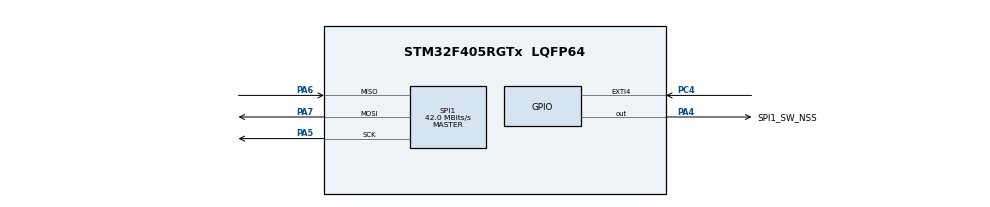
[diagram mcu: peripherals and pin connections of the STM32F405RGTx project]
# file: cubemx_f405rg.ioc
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Dma.Request0=SPI1_RX
Dma.Request1=SPI1_TX
Dma.SPI1_RX.0.Direction=DMA_PERIPH_TO_MEMORY
Dma.SPI1_RX.0.FIFOMode=DMA_FIFOMODE_DISABLE
Dma.SPI1_RX.0.Instance=DMA2_Stream0
Dma.SPI1_RX.0.MemDataAlignment=DMA_MDATAALIGN_BYTE
Dma.SPI1_RX.0.MemInc=DMA_MINC_ENABLE
Dma.SPI1_RX.0.Mode=DMA_NORMAL
Dma.SPI1_RX.0.PeriphDataAlignment=DMA_PDATAALIGN_BYTE
Dma.SPI1_RX.0.PeriphInc=DMA_PINC_DISABLE
Dma.SPI1_RX.0.Priority=DMA_PRIORITY_LOW
Dma.SPI1_TX.1.Direction=DMA_MEMORY_TO_PERIPH
Dma.SPI1_TX.1.FIFOMode=DMA_FIFOMODE_DISABLE
Dma.SPI1_TX.1.Instance=DMA2_Stream3
Dma.SPI1_TX.1.MemDataAlignment=DMA_MDATAALIGN_BYTE
Dma.SPI1_TX.1.MemInc=DMA_MINC_ENABLE
Dma.SPI1_TX.1.Mode=DMA_NORMAL
Dma.SPI1_TX.1.PeriphDataAlignment=DMA_PDATAALIGN_BYTE
Dma.SPI1_TX.1.PeriphInc=DMA_PINC_DISABLE
Dma.SPI1_TX.1.Priority=DMA_PRIORITY_LOW
Mcu.Family=STM32F4
Mcu.Name=STM32F405RGTx
Mcu.Package=LQFP64
NVIC.DMA2_Stream0_IRQn=true\:0\:0\:false\:false\:true\:false\:true
NVIC.DMA2_Stream3_IRQn=true\:0\:0\:false\:false\:true\:false\:true
NVIC.EXTI4_IRQn=true\:0\:0\:false\:false\:true\:true\:true
NVIC.PriorityGroup=NVIC_PRIORITYGROUP_4
NVIC.SPI1_IRQn=true\:0\:0\:false\:false\:true\:true\:true
PA13.Mode=Serial_Wire
PA13.Signal=SYS_JTMS-SWDIO
PA14.Mode=Serial_Wire
PA14.Signal=SYS_JTCK-SWCLK
PA4.GPIO_Label=SPI1_SW_NSS
PA4.Signal=GPIO_Output
PA5.Mode=Full_Duplex_Master
PA5.Signal=SPI1_SCK
PA6.Mode=Full_Duplex_Master
PA6.Signal=SPI1_MISO
PA7.Mode=Full_Duplex_Master
PA7.Signal=SPI1_MOSI
PC4.Signal=GPXTI4
PH0-OSC_IN.Mode=HSE-External-Oscillator
PH0-OSC_IN.Signal=RCC_OSC_IN
PH1-OSC_OUT.Mode=HSE-External-Oscillator
PH1-OSC_OUT.Signal=RCC_OSC_OUT
ProjectManager.HeapSize=0x200
ProjectManager.StackSize=0x400
ProjectManager.TargetToolchain=Makefile
RCC.48MHZClocksFreq_Value=84000000
RCC.AHBFreq_Value=168000000
RCC.APB1CLKDivider=RCC_HCLK_DIV4
RCC.APB1Freq_Value=42000000
RCC.APB1TimFreq_Value=84000000
RCC.APB2CLKDivider=RCC_HCLK_DIV2
RCC.APB2Freq_Value=84000000
RCC.APB2TimFreq_Value=168000000
RCC.CortexFreq_Value=168000000
RCC.HCLKFreq_Value=168000000
RCC.HSE_VALUE=8000000
RCC.HSI_VALUE=16000000
RCC.LSE_VALUE=32768
RCC.PLLM=4
RCC.PLLN=168
RCC.PLLSourceVirtual=RCC_PLLSOURCE_HSE
RCC.RCC_RTC_Clock_SourceVirtual=RCC_RTCCLKSOURCE_HSE_DIV8
RCC.RCC_RTC_Clock_Source_FROM_HSE=RCC_RTCCLKSOURCE_HSE_DIV8
RCC.SYSCLKFreq_VALUE=168000000
RCC.SYSCLKSource=RCC_SYSCLKSOURCE_PLLCLK
RCC.VCOOutputFreq_Value=336000000
SPI1.CalculateBaudRate=42.0 MBits/s
SPI1.Direction=SPI_DIRECTION_2LINES
SPI1.Mode=SPI_MODE_MASTER
SPI1.VirtualType=VM_MASTER
VP_RTC_VS_RTC_Activate.Mode=RTC_Enabled
board=custom

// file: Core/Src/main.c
/* USER CODE BEGIN Header */
/**
  ******************************************************************************
  * @file           : main.c
  * @brief          : Main program body
  ******************************************************************************
  * @attention
  *
  * <h2><center>&copy; Copyright (c) 2022 STMicroelectronics.
  * All rights reserved.</center></h2>
  *
  * This software component is licensed by ST under BSD 3-Clause license,
  * the "License"; You may not use this file except in compliance with the
  * License. You may obtain a copy of the License at:
  *                        opensource.org/licenses/BSD-3-Clause
  *
  ******************************************************************************
  */
/* USER CODE END Header */
#include "main.h"

void SystemClock_Config(void);
static void MX_GPIO_Init(void);
static void MX_DMA_Init(void);
static void MX_SPI1_Init(void);
static void MX_RTC_Init(void);

int main(void)
{

  /* MCU Configuration--------------------------------------------------------*/

  /* Reset of all peripherals, Initializes the Flash interface and the Systick. */

  LL_APB2_GRP1_EnableClock(LL_APB2_GRP1_PERIPH_SYSCFG);
  LL_APB1_GRP1_EnableClock(LL_APB1_GRP1_PERIPH_PWR);

  NVIC_SetPriorityGrouping(NVIC_PRIORITYGROUP_4);

  /* System interrupt init*/
  /* SysTick_IRQn interrupt configuration */
  NVIC_SetPriority(SysTick_IRQn, NVIC_EncodePriority(NVIC_GetPriorityGrouping(),15, 0));

  /* Configure the system clock */
  SystemClock_Config();

  /* Initialize all configured peripherals */
  MX_GPIO_Init();
  MX_DMA_Init();
  MX_SPI1_Init();
  MX_RTC_Init();

  /* Infinite loop */
  while (1)
  {

  }
}

void SystemClock_Config(void)
{
  LL_FLASH_SetLatency(LL_FLASH_LATENCY_5);
  while(LL_FLASH_GetLatency()!= LL_FLASH_LATENCY_5)
  {
  }
  LL_PWR_SetRegulVoltageScaling(LL_PWR_REGU_VOLTAGE_SCALE1);
  LL_RCC_HSE_Enable();

   /* Wait till HSE is ready */
  while(LL_RCC_HSE_IsReady() != 1)
  {

  }
  LL_PWR_EnableBkUpAccess();
  LL_RCC_PLL_ConfigDomain_SYS(LL_RCC_PLLSOURCE_HSE, LL_RCC_PLLM_DIV_4, 168, LL_RCC_PLLP_DIV_2);
  LL_RCC_PLL_Enable();

   /* Wait till PLL is ready */
  while(LL_RCC_PLL_IsReady() != 1)
  {

  }
  LL_RCC_SetAHBPrescaler(LL_RCC_SYSCLK_DIV_1);
  LL_RCC_SetAPB1Prescaler(LL_RCC_APB1_DIV_4);
  LL_RCC_SetAPB2Prescaler(LL_RCC_APB2_DIV_2);
  LL_RCC_SetSysClkSource(LL_RCC_SYS_CLKSOURCE_PLL);

   /* Wait till System clock is ready */
  while(LL_RCC_GetSysClkSource() != LL_RCC_SYS_CLKSOURCE_STATUS_PLL)
  {

  }
  LL_Init1msTick(168000000);
  LL_SetSystemCoreClock(168000000);
}

static void MX_RTC_Init(void)
{

  LL_RTC_InitTypeDef RTC_InitStruct = {0};

  if(LL_RCC_GetRTCClockSource() != LL_RCC_RTC_CLKSOURCE_HSE)
  {
    LL_RCC_ForceBackupDomainReset();
    LL_RCC_ReleaseBackupDomainReset();
  LL_RCC_SetRTCClockSource(LL_RCC_RTC_CLKSOURCE_HSE);
  }
  LL_RCC_SetRTC_HSEPrescaler(LL_RCC_RTC_HSE_DIV_8);

  /* Peripheral clock enable */
  LL_RCC_EnableRTC();

  /** Initialize RTC and set the Time and Date
  */
  RTC_InitStruct.HourFormat = LL_RTC_HOURFORMAT_24HOUR;
  RTC_InitStruct.AsynchPrescaler = 127;
  RTC_InitStruct.SynchPrescaler = 255;
  LL_RTC_Init(RTC, &RTC_InitStruct);
  LL_RTC_SetAsynchPrescaler(RTC, 127);
  LL_RTC_SetSynchPrescaler(RTC, 255);

}

static void MX_SPI1_Init(void)
{

  LL_SPI_InitTypeDef SPI_InitStruct = {0};

  LL_GPIO_InitTypeDef GPIO_InitStruct = {0};

  /* Peripheral clock enable */
  LL_APB2_GRP1_EnableClock(LL_APB2_GRP1_PERIPH_SPI1);

  LL_AHB1_GRP1_EnableClock(LL_AHB1_GRP1_PERIPH_GPIOA);
  /**SPI1 GPIO Configuration
  PA5   ------> SPI1_SCK
  PA6   ------> SPI1_MISO
  PA7   ------> SPI1_MOSI
  */
  GPIO_InitStruct.Pin = LL_GPIO_PIN_5|LL_GPIO_PIN_6|LL_GPIO_PIN_7;
  GPIO_InitStruct.Mode = LL_GPIO_MODE_ALTERNATE;
  GPIO_InitStruct.Speed = LL_GPIO_SPEED_FREQ_VERY_HIGH;
  GPIO_InitStruct.OutputType = LL_GPIO_OUTPUT_PUSHPULL;
  GPIO_InitStruct.Pull = LL_GPIO_PULL_NO;
  GPIO_InitStruct.Alternate = LL_GPIO_AF_5;
  LL_GPIO_Init(GPIOA, &GPIO_InitStruct);

  /* SPI1 DMA Init */

  /* SPI1_RX Init */
  LL_DMA_SetChannelSelection(DMA2, LL_DMA_STREAM_0, LL_DMA_CHANNEL_3);

  LL_DMA_SetDataTransferDirection(DMA2, LL_DMA_STREAM_0, LL_DMA_DIRECTION_PERIPH_TO_MEMORY);

  LL_DMA_SetStreamPriorityLevel(DMA2, LL_DMA_STREAM_0, LL_DMA_PRIORITY_LOW);

  LL_DMA_SetMode(DMA2, LL_DMA_STREAM_0, LL_DMA_MODE_NORMAL);

  LL_DMA_SetPeriphIncMode(DMA2, LL_DMA_STREAM_0, LL_DMA_PERIPH_NOINCREMENT);

  LL_DMA_SetMemoryIncMode(DMA2, LL_DMA_STREAM_0, LL_DMA_MEMORY_INCREMENT);

  LL_DMA_SetPeriphSize(DMA2, LL_DMA_STREAM_0, LL_DMA_PDATAALIGN_BYTE);

  LL_DMA_SetMemorySize(DMA2, LL_DMA_STREAM_0, LL_DMA_MDATAALIGN_BYTE);

  LL_DMA_DisableFifoMode(DMA2, LL_DMA_STREAM_0);

  /* SPI1_TX Init */
  LL_DMA_SetChannelSelection(DMA2, LL_DMA_STREAM_3, LL_DMA_CHANNEL_3);

  LL_DMA_SetDataTransferDirection(DMA2, LL_DMA_STREAM_3, LL_DMA_DIRECTION_MEMORY_TO_PERIPH);

  LL_DMA_SetStreamPriorityLevel(DMA2, LL_DMA_STREAM_3, LL_DMA_PRIORITY_LOW);

  LL_DMA_SetMode(DMA2, LL_DMA_STREAM_3, LL_DMA_MODE_NORMAL);

  LL_DMA_SetPeriphIncMode(DMA2, LL_DMA_STREAM_3, LL_DMA_PERIPH_NOINCREMENT);

  LL_DMA_SetMemoryIncMode(DMA2, LL_DMA_STREAM_3, LL_DMA_MEMORY_INCREMENT);

  LL_DMA_SetPeriphSize(DMA2, LL_DMA_STREAM_3, LL_DMA_PDATAALIGN_BYTE);

  LL_DMA_SetMemorySize(DMA2, LL_DMA_STREAM_3, LL_DMA_MDATAALIGN_BYTE);

  LL_DMA_DisableFifoMode(DMA2, LL_DMA_STREAM_3);

  /* SPI1 interrupt Init */
  NVIC_SetPriority(SPI1_IRQn, NVIC_EncodePriority(NVIC_GetPriorityGrouping(),0, 0));
  NVIC_EnableIRQ(SPI1_IRQn);

  /* USER CODE BEGIN SPI1_Init 1 */
  /* (5) Enable DMA interrupts complete/error */
  LL_DMA_EnableIT_TC(DMA2, LL_DMA_STREAM_0);
  LL_DMA_EnableIT_TE(DMA2, LL_DMA_STREAM_0);

  LL_DMA_EnableIT_TC(DMA2, LL_DMA_STREAM_3);
  LL_DMA_EnableIT_TE(DMA2, LL_DMA_STREAM_3);

  /* USER CODE END SPI1_Init 1 */
  /* SPI1 parameter configuration*/
  SPI_InitStruct.TransferDirection = LL_SPI_FULL_DUPLEX;
  SPI_InitStruct.Mode = LL_SPI_MODE_MASTER;
  SPI_InitStruct.DataWidth = LL_SPI_DATAWIDTH_8BIT;
  SPI_InitStruct.ClockPolarity = LL_SPI_POLARITY_LOW;
  SPI_InitStruct.ClockPhase = LL_SPI_PHASE_1EDGE;
  SPI_InitStruct.NSS = LL_SPI_NSS_SOFT;
  SPI_InitStruct.BaudRate = LL_SPI_BAUDRATEPRESCALER_DIV2;
  SPI_InitStruct.BitOrder = LL_SPI_MSB_FIRST;
  SPI_InitStruct.CRCCalculation = LL_SPI_CRCCALCULATION_DISABLE;
  SPI_InitStruct.CRCPoly = 10;
  LL_SPI_Init(SPI1, &SPI_InitStruct);
  LL_SPI_SetStandard(SPI1, LL_SPI_PROTOCOL_MOTOROLA);
  /* USER CODE BEGIN SPI1_Init 2 */

  /* Configure SPI1 DMA transfer interrupts */
  /* Enable DMA RX Interrupt */
  LL_SPI_EnableDMAReq_RX(SPI1);
  /* Enable DMA TX Interrupt */
  LL_SPI_EnableDMAReq_TX(SPI1);

  /* USER CODE END SPI1_Init 2 */

}

static void MX_DMA_Init(void)
{

  /* Init with LL driver */
  /* DMA controller clock enable */
  LL_AHB1_GRP1_EnableClock(LL_AHB1_GRP1_PERIPH_DMA2);

  /* DMA interrupt init */
  /* DMA2_Stream0_IRQn interrupt configuration */
  NVIC_SetPriority(DMA2_Stream0_IRQn, NVIC_EncodePriority(NVIC_GetPriorityGrouping(),0, 0));
  NVIC_EnableIRQ(DMA2_Stream0_IRQn);
  /* DMA2_Stream3_IRQn interrupt configuration */
  NVIC_SetPriority(DMA2_Stream3_IRQn, NVIC_EncodePriority(NVIC_GetPriorityGrouping(),0, 0));
  NVIC_EnableIRQ(DMA2_Stream3_IRQn);

}

static void MX_GPIO_Init(void)
{
  LL_EXTI_InitTypeDef EXTI_InitStruct = {0};
  LL_GPIO_InitTypeDef GPIO_InitStruct = {0};

  /* GPIO Ports Clock Enable */
  LL_AHB1_GRP1_EnableClock(LL_AHB1_GRP1_PERIPH_GPIOH);
  LL_AHB1_GRP1_EnableClock(LL_AHB1_GRP1_PERIPH_GPIOA);
  LL_AHB1_GRP1_EnableClock(LL_AHB1_GRP1_PERIPH_GPIOC);

  /**/
  LL_GPIO_ResetOutputPin(SPI1_SW_NSS_GPIO_Port, SPI1_SW_NSS_Pin);

  /**/
  GPIO_InitStruct.Pin = SPI1_SW_NSS_Pin;
  GPIO_InitStruct.Mode = LL_GPIO_MODE_OUTPUT;
  GPIO_InitStruct.Speed = LL_GPIO_SPEED_FREQ_LOW;
  GPIO_InitStruct.OutputType = LL_GPIO_OUTPUT_PUSHPULL;
  GPIO_InitStruct.Pull = LL_GPIO_PULL_NO;
  LL_GPIO_Init(SPI1_SW_NSS_GPIO_Port, &GPIO_InitStruct);

  /**/
  LL_SYSCFG_SetEXTISource(LL_SYSCFG_EXTI_PORTC, LL_SYSCFG_EXTI_LINE4);

  /**/
  EXTI_InitStruct.Line_0_31 = LL_EXTI_LINE_4;
  EXTI_InitStruct.LineCommand = ENABLE;
  EXTI_InitStruct.Mode = LL_EXTI_MODE_IT;
  EXTI_InitStruct.Trigger = LL_EXTI_TRIGGER_RISING;
  LL_EXTI_Init(&EXTI_InitStruct);

  /**/
  LL_GPIO_SetPinPull(GPIOC, LL_GPIO_PIN_4, LL_GPIO_PULL_NO);

  /**/
  LL_GPIO_SetPinMode(GPIOC, LL_GPIO_PIN_4, LL_GPIO_MODE_INPUT);

  /* EXTI interrupt init*/
  NVIC_SetPriority(EXTI4_IRQn, NVIC_EncodePriority(NVIC_GetPriorityGrouping(),0, 0));
  NVIC_EnableIRQ(EXTI4_IRQn);

}

void Error_Handler(void)
{
  __disable_irq();
  while (1)
  {
  }
}

/************************ (C) COPYRIGHT STMicroelectronics *****END OF FILE****/
